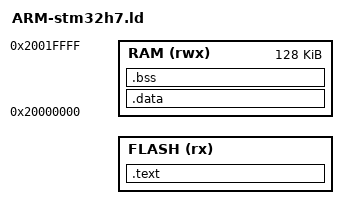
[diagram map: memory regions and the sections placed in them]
MEMORY
{
    FLASH (rx) : ORIGIN = @WOLFBOOT_TEST_APP_ADDRESS@, LENGTH = @WOLFBOOT_TEST_APP_SIZE@
    RAM (rwx) : ORIGIN = 0x20000000, LENGTH = 0x00020000 /* mapping TCM only */
}

SECTIONS
{
    .text :
    {
        _start_text = .;
        KEEP(*(.isr_vector))
        *(.init)
        *(.fini)
        *(.text*)
        *(.rodata*)
        . = ALIGN(4);
        _end_text = .;
    } > FLASH

    _stored_data = .;

    .data : AT (_stored_data)
    {
        _start_data = .;
        KEEP(*(.data*))
        . = ALIGN(4);
        KEEP(*(.ramcode))
        . = ALIGN(4);
        _end_data = .;
    } > RAM

    .bss (NOLOAD) :
    {
        _start_bss = .;
        *(.bss*)
        *(COMMON)
        . = ALIGN(4);
        _end_bss = .;
        _end = .;
    } > RAM
}

_wolfboot_partition_boot_address = 0x8020000;
_wolfboot_partition_size = 0xD0000;
_wolfboot_partition_update_address = 0x80F0000;
_wolfboot_partition_swap_address = 0x81C0000;

PROVIDE(_start_heap = _end);
PROVIDE(_end_stack  = ORIGIN(RAM) + LENGTH(RAM));
